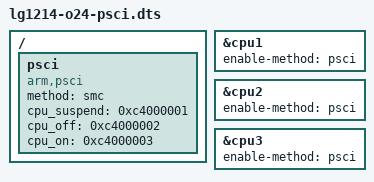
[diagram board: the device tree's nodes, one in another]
#include "lg1214-o24.dtsi"

&cpu1 {
	enable-method = "psci";
};

&cpu2 {
	enable-method = "psci";
};

&cpu3 {
	enable-method = "psci";
};

/ {
	psci {
		compatible = "arm,psci";
		method = "smc";
		cpu_suspend = <0xc4000001>;
		cpu_off = <0xc4000002>;
		cpu_on = <0xc4000003>;
	};
};
